# iospear320 register map
Registers are 32-bit, access not given, no defined reset value unless marked. A register's access mark holds for its fields unless they carry their own. Addresses are absolute; registers are grouped by the start of their names; [hi:lo] are bit positions; {n}, {i} and the like mark numbered series; 'fields as' and 'values as' point back to an identical list.

## ADC
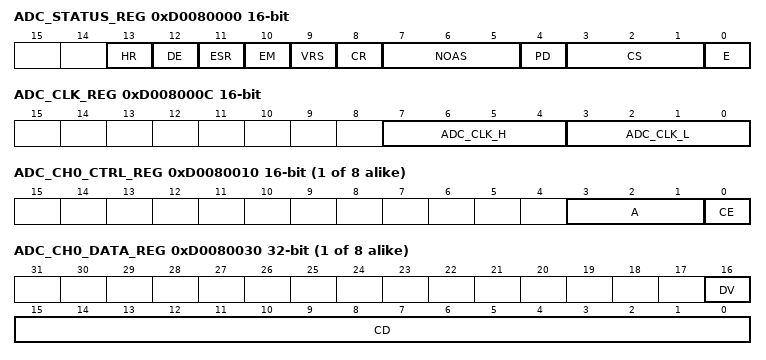
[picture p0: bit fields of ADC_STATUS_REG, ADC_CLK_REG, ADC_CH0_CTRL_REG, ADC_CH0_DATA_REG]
0xD0080000 ADC_STATUS_REG 16-bit
  [13] HR, [12] DE, [11] ESR, [10] EM, [9] VRS, [8] CR, [7:5] NOAS, [4] PD, [3:1] CS, [0] E
0xD0080004 ADC_AVERAGE_REG 16-bit
  [9:0] CD
0xD0080008 ADC_SCAN_RATE_REG
0xD008000C ADC_CLK_REG 16-bit
  [7:4] ADC_CLK_H, [3:0] ADC_CLK_L
{0xD0080010+4i} ADC_CH{i}_CTRL_REG 16-bit (i=0..7)
  [3:1] A, [0] CE
{0xD0080030+4i} ADC_CH{i}_DATA_REG (i=0..7)
  [16] DV, [15:0] CD

## GenMemCtrl
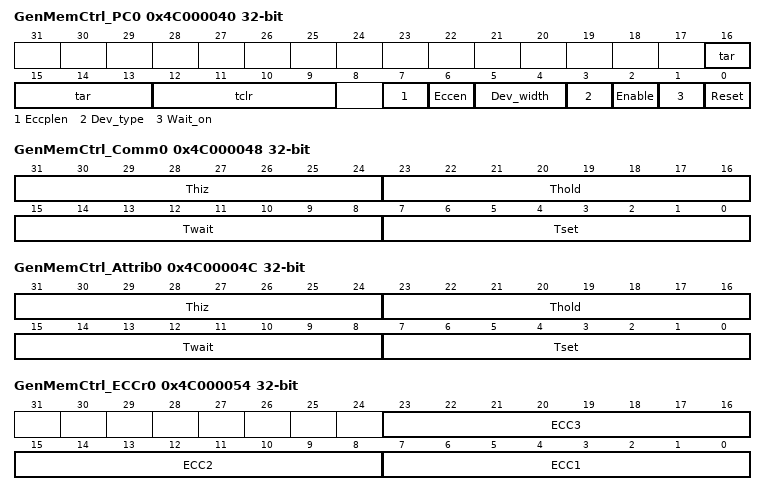
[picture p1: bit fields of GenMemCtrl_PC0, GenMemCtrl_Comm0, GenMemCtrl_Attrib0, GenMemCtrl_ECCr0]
0x4C000040 GenMemCtrl_PC0
  [16:13] tar, [12:9] tclr, [7] Eccplen, [6] Eccen, [5:4] Dev_width, [3] Dev_type, [2] Enable, [1] Wait_on, [0] Reset
0x4C000048 GenMemCtrl_Comm0
  [31:24] Thiz, [23:16] Thold, [15:8] Twait, [7:0] Tset
0x4C00004C GenMemCtrl_Attrib0
  [31:24] Thiz, [23:16] Thold, [15:8] Twait, [7:0] Tset
0x4C000054 GenMemCtrl_ECCr0
  [23:16] ECC3, [15:8] ECC2, [7:0] ECC1
{0x4C000FE0+4i} GenMemCtrl_PeriphID{i} (i=0..3)
{0x4C000FF0+4i} GenMemCtrl_PCellID{i} (i=0..3)

## PWM
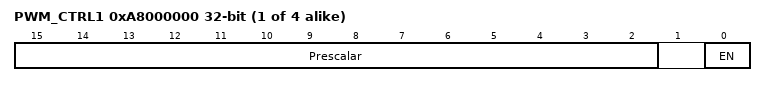
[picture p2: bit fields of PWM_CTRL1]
{0xA7FFFFF0+0x10*i} PWM_CTRL{i} (i=1..4)
  [15:2] Prescalar, [0] EN
{0xA7FFFFF4+0x10*i} PWM_DUTY{i} (i=1..4)
  [15:0] Duty
{0xA7FFFFF8+0x10*i} PWM_PER{i} (i=1..3)
  [15:0] Period
0xA8000038 PWM_PE41
  [15:0] Period

## CAN0
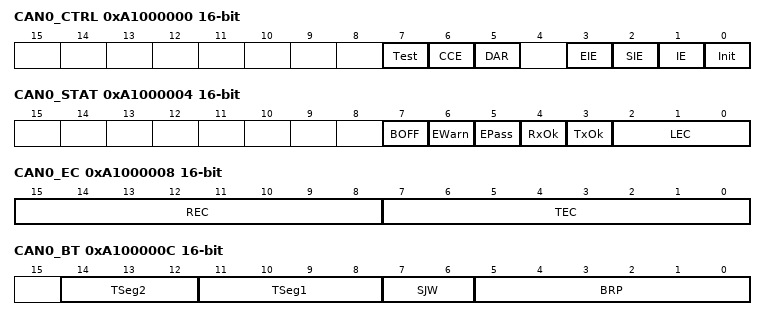
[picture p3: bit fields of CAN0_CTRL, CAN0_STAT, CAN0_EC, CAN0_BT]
0xA1000000 CAN0_CTRL 16-bit
  [7] Test, [6] CCE, [5] DAR, [3] EIE, [2] SIE, [1] IE, [0] Init
0xA1000004 CAN0_STAT 16-bit
  [7] BOFF, [6] EWarn, [5] EPass, [4] RxOk, [3] TxOk, [2:0] LEC
0xA1000008 CAN0_EC 16-bit
  [15:8] REC, [7:0] TEC
0xA100000C CAN0_BT 16-bit
  [14:12] TSeg2, [11:8] TSeg1, [7:6] SJW, [5:0] BRP
0xA1000010 CAN0_INTR 16-bit
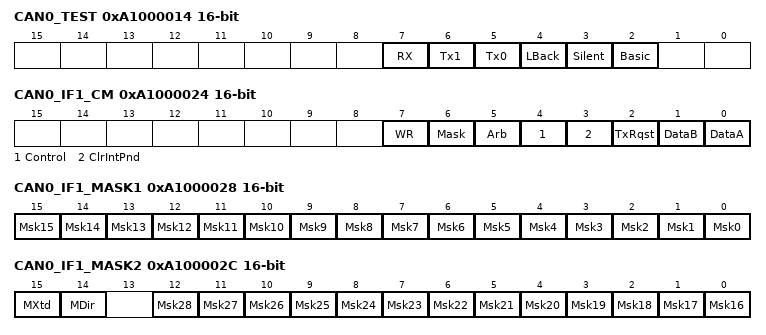
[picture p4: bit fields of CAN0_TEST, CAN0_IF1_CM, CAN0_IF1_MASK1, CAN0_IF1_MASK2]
0xA1000014 CAN0_TEST 16-bit
  [7] RX, [6] Tx1, [5] Tx0, [4] LBack, [3] Silent, [2] Basic
0xA1000018 CAN0_BRPE 16-bit
  [3:0] BRPE
0xA1000020 CAN0_IF1_CMD 16-bit
  [5:0] MN
0xA1000024 CAN0_IF1_CM 16-bit
  [7] WR, [6] Mask, [5] Arb, [4] Control, [3] ClrIntPnd, [2] TxRqst, [1] DataB, [0] DataA
0xA1000028 CAN0_IF1_MASK1 16-bit
  [n] Msk{n} (n=0..15)
0xA100002C CAN0_IF1_MASK2 16-bit
  [15] MXtd, [14] MDir, [n-16] Msk{n} (n=16..28)
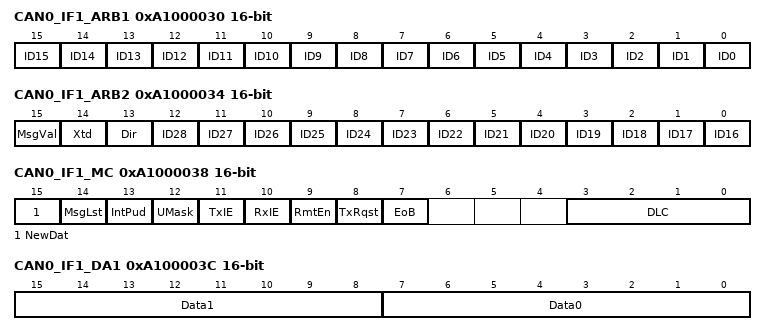
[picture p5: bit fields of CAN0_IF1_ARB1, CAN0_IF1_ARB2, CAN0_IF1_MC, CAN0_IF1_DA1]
0xA1000030 CAN0_IF1_ARB1 16-bit
  [n] ID{n} (n=0..15)
0xA1000034 CAN0_IF1_ARB2 16-bit
  [15] MsgVal, [14] Xtd, [13] Dir, [n-16] ID{n} (n=16..28)
0xA1000038 CAN0_IF1_MC 16-bit
  [15] NewDat, [14] MsgLst, [13] IntPud, [12] UMask, [11] TxIE, [10] RxIE, [9] RmtEn, [8] TxRqst, [7] EoB, [3:0] DLC
0xA100003C CAN0_IF1_DA1 16-bit
  [15:8] Data1, [7:0] Data0
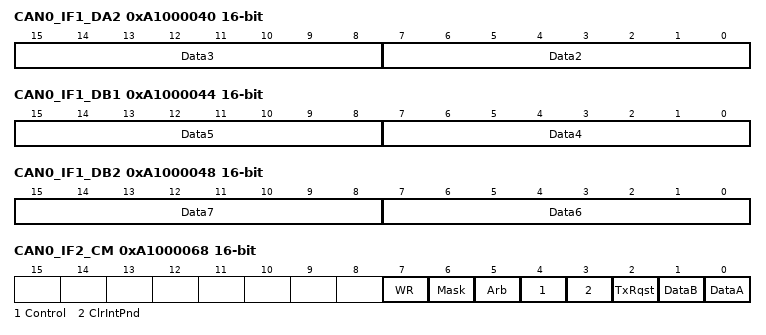
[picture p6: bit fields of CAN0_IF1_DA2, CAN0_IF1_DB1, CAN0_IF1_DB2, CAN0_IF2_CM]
0xA1000040 CAN0_IF1_DA2 16-bit
  [15:8] Data3, [7:0] Data2
0xA1000044 CAN0_IF1_DB1 16-bit
  [15:8] Data5, [7:0] Data4
0xA1000048 CAN0_IF1_DB2 16-bit
  [15:8] Data7, [7:0] Data6
0xA1000064 CAN0_IF2_CMD 16-bit
  [5:0] MN
0xA1000068 CAN0_IF2_CM 16-bit
  fields as CAN0_IF1_CM
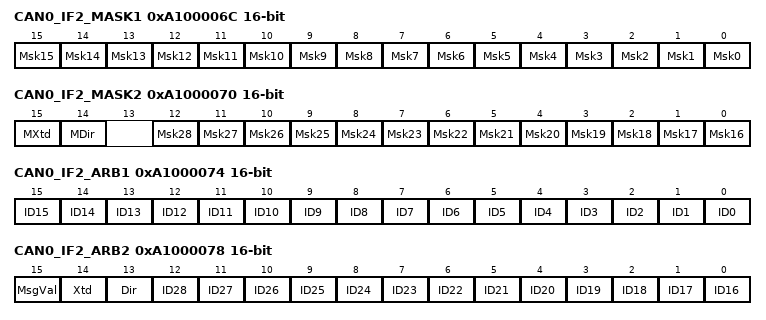
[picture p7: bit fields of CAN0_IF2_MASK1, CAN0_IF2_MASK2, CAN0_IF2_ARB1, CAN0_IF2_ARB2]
0xA100006C CAN0_IF2_MASK1 16-bit
  [n] Msk{n} (n=0..15)
0xA1000070 CAN0_IF2_MASK2 16-bit
  [15] MXtd, [14] MDir, [n-16] Msk{n} (n=16..28)
0xA1000074 CAN0_IF2_ARB1 16-bit
  [n] ID{n} (n=0..15)
0xA1000078 CAN0_IF2_ARB2 16-bit
  [15] MsgVal, [14] Xtd, [13] Dir, [n-16] ID{n} (n=16..28)
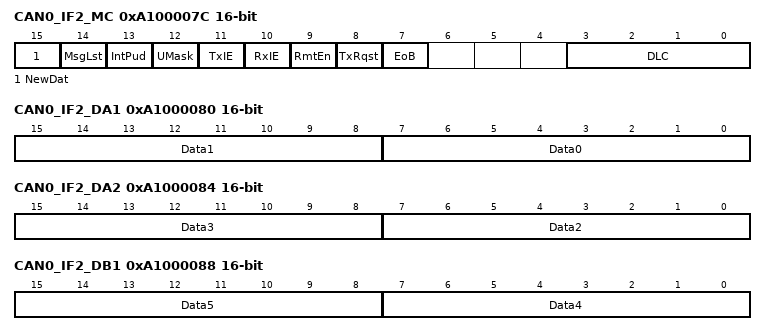
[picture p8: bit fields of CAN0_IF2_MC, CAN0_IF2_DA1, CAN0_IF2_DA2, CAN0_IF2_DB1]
0xA100007C CAN0_IF2_MC 16-bit
  fields as CAN0_IF1_MC
0xA1000080 CAN0_IF2_DA1 16-bit
  [15:8] Data1, [7:0] Data0
0xA1000084 CAN0_IF2_DA2 16-bit
  [15:8] Data3, [7:0] Data2
0xA1000088 CAN0_IF2_DB1 16-bit
  [15:8] Data5, [7:0] Data4
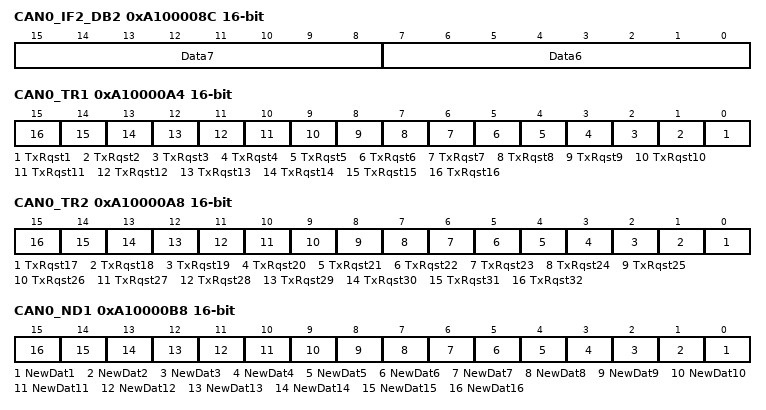
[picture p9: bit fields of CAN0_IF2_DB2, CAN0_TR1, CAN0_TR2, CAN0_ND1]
0xA100008C CAN0_IF2_DB2 16-bit
  [15:8] Data7, [7:0] Data6
0xA10000A4 CAN0_TR1 16-bit
  [n-1] TxRqst{n} (n=1..16)
0xA10000A8 CAN0_TR2 16-bit
  [n-17] TxRqst{n} (n=17..32)
0xA10000B8 CAN0_ND1 16-bit
  [n-1] NewDat{n} (n=1..16)
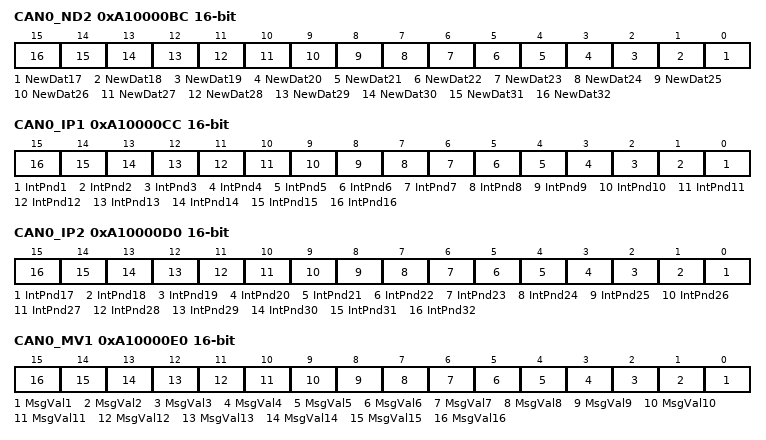
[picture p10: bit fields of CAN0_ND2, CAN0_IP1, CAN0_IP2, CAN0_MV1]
0xA10000BC CAN0_ND2 16-bit
  [n-17] NewDat{n} (n=17..32)
0xA10000CC CAN0_IP1 16-bit
  [n-1] IntPnd{n} (n=1..16)
0xA10000D0 CAN0_IP2 16-bit
  [n-17] IntPnd{n} (n=17..32)
0xA10000E0 CAN0_MV1 16-bit
  [n-1] MsgVal{n} (n=1..16)
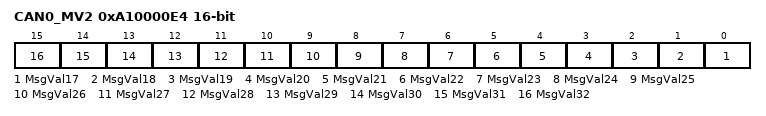
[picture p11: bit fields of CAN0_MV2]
0xA10000E4 CAN0_MV2 16-bit
  [n-17] MsgVal{n} (n=17..32)

## CAN1
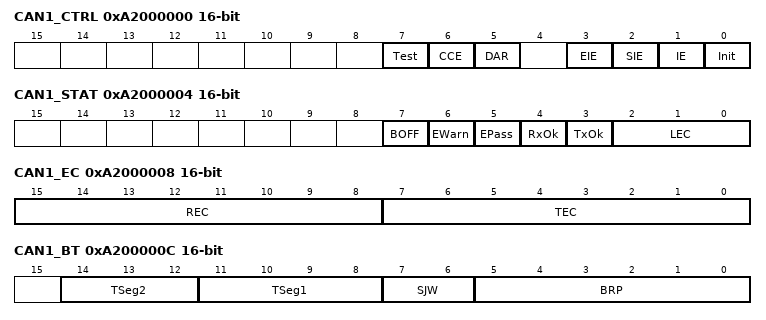
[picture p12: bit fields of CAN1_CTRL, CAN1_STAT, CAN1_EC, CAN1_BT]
0xA2000000 CAN1_CTRL 16-bit
  [7] Test, [6] CCE, [5] DAR, [3] EIE, [2] SIE, [1] IE, [0] Init
0xA2000004 CAN1_STAT 16-bit
  [7] BOFF, [6] EWarn, [5] EPass, [4] RxOk, [3] TxOk, [2:0] LEC
0xA2000008 CAN1_EC 16-bit
  [15:8] REC, [7:0] TEC
0xA200000C CAN1_BT 16-bit
  [14:12] TSeg2, [11:8] TSeg1, [7:6] SJW, [5:0] BRP
0xA2000010 CAN1_INTR 16-bit
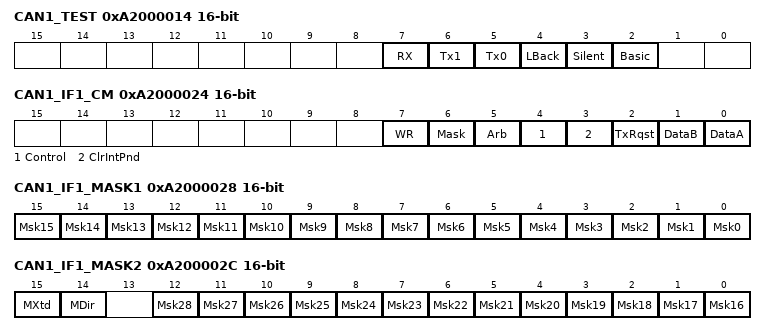
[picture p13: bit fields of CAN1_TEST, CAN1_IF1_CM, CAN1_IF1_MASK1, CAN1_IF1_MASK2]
0xA2000014 CAN1_TEST 16-bit
  [7] RX, [6] Tx1, [5] Tx0, [4] LBack, [3] Silent, [2] Basic
0xA2000018 CAN1_BRPE 16-bit
  [3:0] BRPE
0xA2000020 CAN1_IF1_CMD 16-bit
  [5:0] MN
0xA2000024 CAN1_IF1_CM 16-bit
  [7] WR, [6] Mask, [5] Arb, [4] Control, [3] ClrIntPnd, [2] TxRqst, [1] DataB, [0] DataA
0xA2000028 CAN1_IF1_MASK1 16-bit
  [n] Msk{n} (n=0..15)
0xA200002C CAN1_IF1_MASK2 16-bit
  [15] MXtd, [14] MDir, [n-16] Msk{n} (n=16..28)
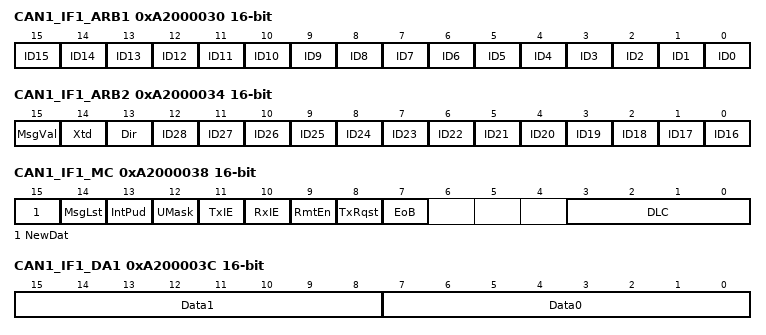
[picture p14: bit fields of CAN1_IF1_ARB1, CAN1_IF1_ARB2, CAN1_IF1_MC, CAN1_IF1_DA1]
0xA2000030 CAN1_IF1_ARB1 16-bit
  [n] ID{n} (n=0..15)
0xA2000034 CAN1_IF1_ARB2 16-bit
  [15] MsgVal, [14] Xtd, [13] Dir, [n-16] ID{n} (n=16..28)
0xA2000038 CAN1_IF1_MC 16-bit
  [15] NewDat, [14] MsgLst, [13] IntPud, [12] UMask, [11] TxIE, [10] RxIE, [9] RmtEn, [8] TxRqst, [7] EoB, [3:0] DLC
0xA200003C CAN1_IF1_DA1 16-bit
  [15:8] Data1, [7:0] Data0
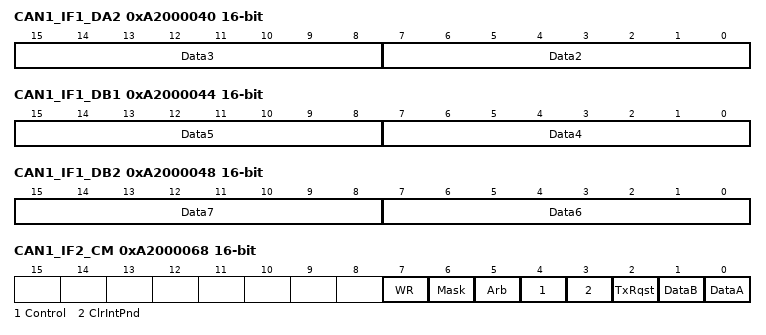
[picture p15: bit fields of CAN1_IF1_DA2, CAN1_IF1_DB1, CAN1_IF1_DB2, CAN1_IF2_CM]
0xA2000040 CAN1_IF1_DA2 16-bit
  [15:8] Data3, [7:0] Data2
0xA2000044 CAN1_IF1_DB1 16-bit
  [15:8] Data5, [7:0] Data4
0xA2000048 CAN1_IF1_DB2 16-bit
  [15:8] Data7, [7:0] Data6
0xA2000064 CAN1_IF2_CMD 16-bit
  [5:0] MN
0xA2000068 CAN1_IF2_CM 16-bit
  fields as CAN1_IF1_CM
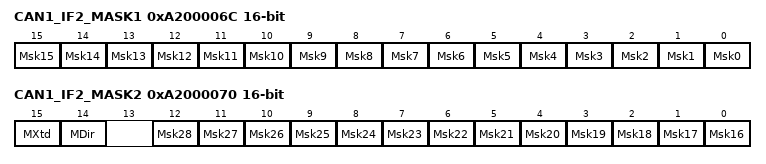
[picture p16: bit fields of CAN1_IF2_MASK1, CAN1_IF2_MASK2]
0xA200006C CAN1_IF2_MASK1 16-bit
  [n] Msk{n} (n=0..15)
0xA2000070 CAN1_IF2_MASK2 16-bit
  [15] MXtd, [14] MDir, [n-16] Msk{n} (n=16..28)
0xA2000074 CAN1_IF2_ARB1 16-bit
  [n] ID{n} (n=0..15)
0xA2000078 CAN1_IF2_ARB2 16-bit
  [15] MsgVal, [14] Xtd, [13] Dir, [n-16] ID{n} (n=16..28)
0xA200007C CAN1_IF2_MC 16-bit
  fields as CAN1_IF1_MC
0xA2000080 CAN1_IF2_DA1 16-bit
  [15:8] Data1, [7:0] Data0
0xA2000084 CAN1_IF2_DA2 16-bit
  [15:8] Data3, [7:0] Data2
0xA2000088 CAN1_IF2_DB1 16-bit
  [15:8] Data5, [7:0] Data4
0xA200008C CAN1_IF2_DB2 16-bit
  [15:8] Data7, [7:0] Data6
0xA20000A4 CAN1_TR1 16-bit
  [n-1] TxRqst{n} (n=1..16)
0xA20000A8 CAN1_TR2 16-bit
  [n-17] TxRqst{n} (n=17..32)
0xA20000B8 CAN1_ND1 16-bit
  [n-1] NewDat{n} (n=1..16)
0xA20000BC CAN1_ND2 16-bit
  [n-17] NewDat{n} (n=17..32)
0xA20000CC CAN1_IP1 16-bit
  [n-1] IntPnd{n} (n=1..16)
0xA20000D0 CAN1_IP2 16-bit
  [n-17] IntPnd{n} (n=17..32)
0xA20000E0 CAN1_MV1 16-bit
  [n-1] MsgVal{n} (n=1..16)
0xA20000E4 CAN1_MV2 16-bit
  [n-17] MsgVal{n} (n=17..32)
